# ESP32-C3 register map
Vendor: ESPRESSIF SYSTEMS (SHANGHAI) CO., LTD.; Series: ESP32 C-Series; File version: 19
CPU: RV32IMC r0p0, little endian, no MPU, no FPU, 0 interrupt priority bits
Address unit: 32 bits
Registers are 32-bit, read-write, reset 0x0 unless marked. A register's access mark holds for its fields unless they carry their own. Offsets are from the block's base; [hi:lo] are bit positions; {n}, {i} and the like mark numbered series.

## RTC_CNTL — Real-Time Clock Control
Base 0x60008000
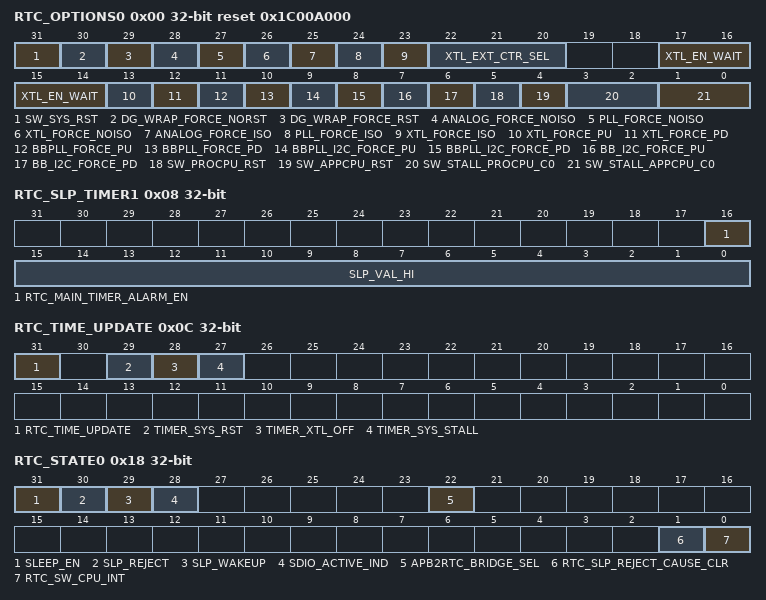
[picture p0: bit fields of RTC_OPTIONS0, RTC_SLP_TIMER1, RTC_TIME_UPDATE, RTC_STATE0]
0x00 RTC_OPTIONS0 access per field reset 0x1C00A000 — rtc configure register
  [31] SW_SYS_RST wo — SW system reset
  [30] DG_WRAP_FORCE_NORST rw — digital core force no reset in deep sleep
  [29] DG_WRAP_FORCE_RST rw — digital wrap force reset in deep sleep
  [28] ANALOG_FORCE_NOISO rw — analog configure
  [27] PLL_FORCE_NOISO rw — analog configure
  [26] XTL_FORCE_NOISO rw — analog configure
  [25] ANALOG_FORCE_ISO rw — analog configure
  [24] PLL_FORCE_ISO rw — analog configure
  [23] XTL_FORCE_ISO rw — analog configure
  [22:20] XTL_EXT_CTR_SEL rw — analog configure
  [17:14] XTL_EN_WAIT rw — wait bias_sleep and current source wakeup
  [13] XTL_FORCE_PU rw — crystall force power up
  [12] XTL_FORCE_PD rw — crystall force power down
  [11] BBPLL_FORCE_PU rw — BB_PLL force power up
  [10] BBPLL_FORCE_PD rw — BB_PLL force power down
  [9] BBPLL_I2C_FORCE_PU rw — BB_PLL_I2C force power up
  [8] BBPLL_I2C_FORCE_PD rw — BB_PLL _I2C force power down
  [7] BB_I2C_FORCE_PU rw — BB_I2C force power up
  [6] BB_I2C_FORCE_PD rw — BB_I2C force power down
  [5] SW_PROCPU_RST wo — PRO CPU SW reset
  [4] SW_APPCPU_RST wo — APP CPU SW reset
  [3:2] SW_STALL_PROCPU_C0 rw — {reg_sw_stall_procpu_c1[5:0], reg_sw_stall_procpu_c0[1:0]} == 0x86 will stall PRO CPU
  [1:0] SW_STALL_APPCPU_C0 rw — {reg_sw_stall_appcpu_c1[5:0], reg_sw_stall_appcpu_c0[1:0]} == 0x86 will stall APP CPU
0x04 RTC_SLP_TIMER0 — rtc configure register
  [31:0] SLP_VAL_LO — configure the sleep time
0x08 RTC_SLP_TIMER1 access per field — rtc configure register
  [16] RTC_MAIN_TIMER_ALARM_EN wo — timer alarm enable bit
  [15:0] SLP_VAL_HI rw — RTC sleep timer high 16 bits
0x0C RTC_TIME_UPDATE access per field — rtc configure register
  [31] RTC_TIME_UPDATE wo — Set 1: to update register with RTC timer
  [29] TIMER_SYS_RST rw — enable to record system reset time
  [28] TIMER_XTL_OFF rw — Enable to record 40M XTAL OFF time
  [27] TIMER_SYS_STALL rw — Enable to record system stall time
0x10 RTC_TIME_LOW0 ro — rtc configure register
  [31:0] RTC_TIMER_VALUE0_LOW — RTC timer low 32 bits
0x14 RTC_TIME_HIGH0 ro — rtc configure register
  [15:0] RTC_TIMER_VALUE0_HIGH — RTC timer high 16 bits
0x18 RTC_STATE0 access per field — rtc configure register
  [31] SLEEP_EN rw — sleep enable bit
  [30] SLP_REJECT rw — leep reject bit
  [29] SLP_WAKEUP rw — leep wakeup bit
  [28] SDIO_ACTIVE_IND ro — SDIO active indication
  [22] APB2RTC_BRIDGE_SEL rw — 1: APB to RTC using bridge
  [1] RTC_SLP_REJECT_CAUSE_CLR wo — clear rtc sleep reject cause
  [0] RTC_SW_CPU_INT wo — rtc software interrupt to main cpu
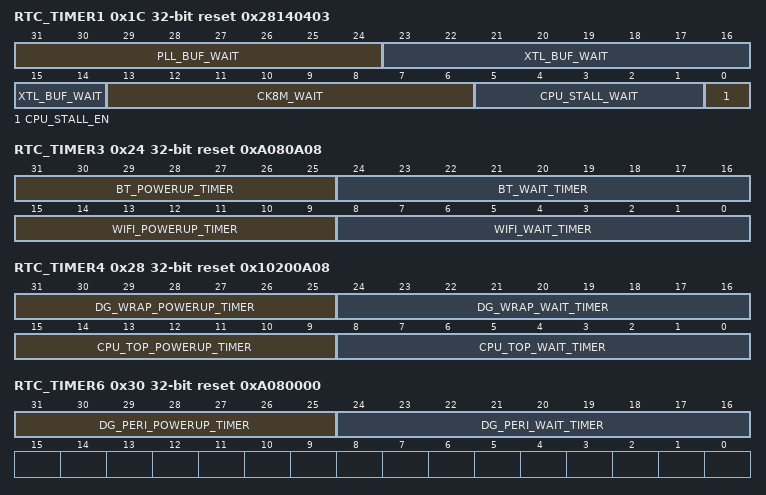
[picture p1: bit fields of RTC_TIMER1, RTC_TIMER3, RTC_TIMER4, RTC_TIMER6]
0x1C RTC_TIMER1 reset 0x28140403 — rtc configure register
  [31:24] PLL_BUF_WAIT — PLL wait cycles in slow_clk_rtc
  [23:14] XTL_BUF_WAIT — XTAL wait cycles in slow_clk_rtc
  [13:6] CK8M_WAIT — CK8M wait cycles in slow_clk_rtc
  [5:1] CPU_STALL_WAIT — CPU stall wait cycles in fast_clk_rtc
  [0] CPU_STALL_EN — CPU stall enable bit
0x20 RTC_TIMER2 reset 0x1000000 — rtc configure register
  [31:24] MIN_TIME_CK8M_OFF — minimal cycles in slow_clk_rtc for CK8M in power down state
0x24 RTC_TIMER3 reset 0xA080A08 — rtc configure register
  [31:25] BT_POWERUP_TIMER — bt power domain power on time
  [24:16] BT_WAIT_TIMER — bt power domain wakeup time
  [15:9] WIFI_POWERUP_TIMER — wifi power domain power on time
  [8:0] WIFI_WAIT_TIMER — wifi power domain wakeup time
0x28 RTC_TIMER4 reset 0x10200A08 — rtc configure register
  [31:25] DG_WRAP_POWERUP_TIMER — digital wrap power domain power on time
  [24:16] DG_WRAP_WAIT_TIMER — digital wrap power domain wakeup time
  [15:9] CPU_TOP_POWERUP_TIMER — cpu top power domain power on time
  [8:0] CPU_TOP_WAIT_TIMER — cpu top power domain wakeup time
0x2C RTC_TIMER5 reset 0x8000 — rtc configure register
  [15:8] MIN_SLP_VAL — minimal sleep cycles in slow_clk_rtc
0x30 RTC_TIMER6 reset 0xA080000 — rtc configure register
  [31:25] DG_PERI_POWERUP_TIMER — digital peri power domain power on time
  [24:16] DG_PERI_WAIT_TIMER — digital peri power domain wakeup time
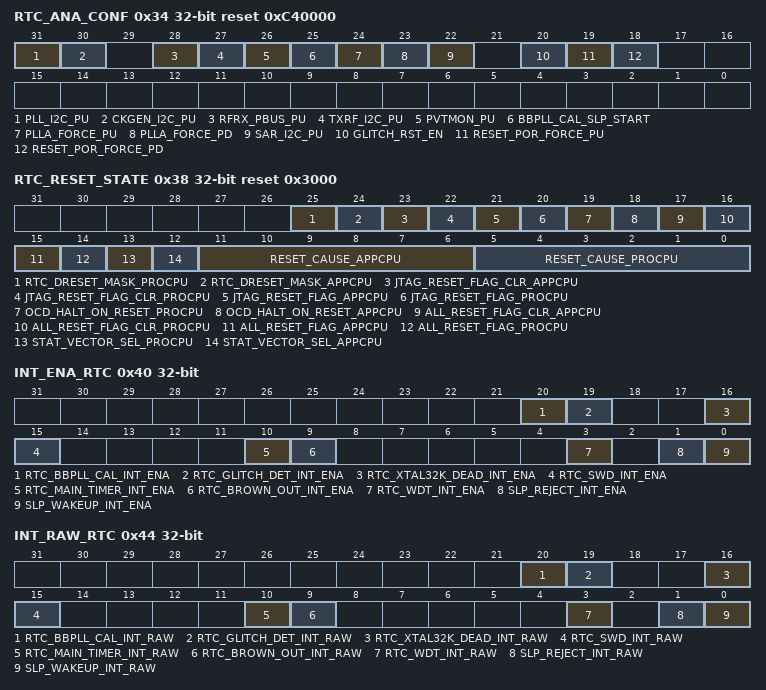
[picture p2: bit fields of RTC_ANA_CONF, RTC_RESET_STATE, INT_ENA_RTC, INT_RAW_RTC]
0x34 RTC_ANA_CONF reset 0xC40000 — rtc configure register
  [31] PLL_I2C_PU — power up pll i2c
  [30] CKGEN_I2C_PU — 1: CKGEN_I2C power up
  [28] RFRX_PBUS_PU — 1: RFRX_PBUS power up
  [27] TXRF_I2C_PU — 1: TXRF_I2C power up
  [26] PVTMON_PU — 1: PVTMON power up
  [25] BBPLL_CAL_SLP_START — start BBPLL calibration during sleep
  [24] PLLA_FORCE_PU — PLLA force power up
  [23] PLLA_FORCE_PD — PLLA force power down
  [22] SAR_I2C_PU — PLLA force power up
  [20] GLITCH_RST_EN — enable glitch reset
  [19] RESET_POR_FORCE_PU — force bypass i2c power on reset
  [18] RESET_POR_FORCE_PD — force no bypass i2c power on reset
0x38 RTC_RESET_STATE access per field reset 0x3000 — rtc configure register
  [25] RTC_DRESET_MASK_PROCPU rw — configure dreset configure
  [24] RTC_DRESET_MASK_APPCPU rw — configure dreset configure
  [23] JTAG_RESET_FLAG_CLR_APPCPU wo — configure jtag reset configure
  [22] JTAG_RESET_FLAG_CLR_PROCPU wo — configure jtag reset configure
  [21] JTAG_RESET_FLAG_APPCPU ro — configure jtag reset configure
  [20] JTAG_RESET_FLAG_PROCPU ro — configure jtag reset configure
  [19] OCD_HALT_ON_RESET_PROCPU rw — PROCPU OcdHaltOnReset
  [18] OCD_HALT_ON_RESET_APPCPU rw — APPCPU OcdHaltOnReset
  [17] ALL_RESET_FLAG_CLR_APPCPU wo — clear APP CPU reset flag
  [16] ALL_RESET_FLAG_CLR_PROCPU wo — clear PRO CPU reset_flag
  [15] ALL_RESET_FLAG_APPCPU ro — APP CPU reset flag
  [14] ALL_RESET_FLAG_PROCPU ro — PRO CPU reset_flag
  [13] STAT_VECTOR_SEL_PROCPU rw — PRO CPU state vector sel
  [12] STAT_VECTOR_SEL_APPCPU rw — APP CPU state vector sel
  [11:6] RESET_CAUSE_APPCPU ro — reset cause of APP CPU
  [5:0] RESET_CAUSE_PROCPU ro — reset cause of PRO CPU
0x3C RTC_WAKEUP_STATE reset 0x60000 — rtc configure register
  [31:15] RTC_WAKEUP_ENA — wakeup enable bitmap
0x40 INT_ENA_RTC — rtc configure register
  [20] RTC_BBPLL_CAL_INT_ENA — enbale bbpll cal end interrupt
  [19] RTC_GLITCH_DET_INT_ENA — enbale gitch det interrupt
  [16] RTC_XTAL32K_DEAD_INT_ENA — enable xtal32k_dead interrupt
  [15] RTC_SWD_INT_ENA — enable super watch dog interrupt
  [10] RTC_MAIN_TIMER_INT_ENA — enable RTC main timer interrupt
  [9] RTC_BROWN_OUT_INT_ENA — enable brown out interrupt
  [3] RTC_WDT_INT_ENA — enable RTC WDT interrupt
  [1] SLP_REJECT_INT_ENA — enable sleep reject interrupt
  [0] SLP_WAKEUP_INT_ENA — enable sleep wakeup interrupt
0x44 INT_RAW_RTC ro — rtc configure register
  [20] RTC_BBPLL_CAL_INT_RAW — bbpll cal end interrupt state
  [19] RTC_GLITCH_DET_INT_RAW — glitch_det_interrupt_raw
  [16] RTC_XTAL32K_DEAD_INT_RAW — xtal32k dead detection interrupt raw
  [15] RTC_SWD_INT_RAW — super watch dog interrupt raw
  [10] RTC_MAIN_TIMER_INT_RAW — RTC main timer interrupt raw
  [9] RTC_BROWN_OUT_INT_RAW — brown out interrupt raw
  [3] RTC_WDT_INT_RAW — RTC WDT interrupt raw
  [1] SLP_REJECT_INT_RAW — sleep reject interrupt raw
  [0] SLP_WAKEUP_INT_RAW — sleep wakeup interrupt raw
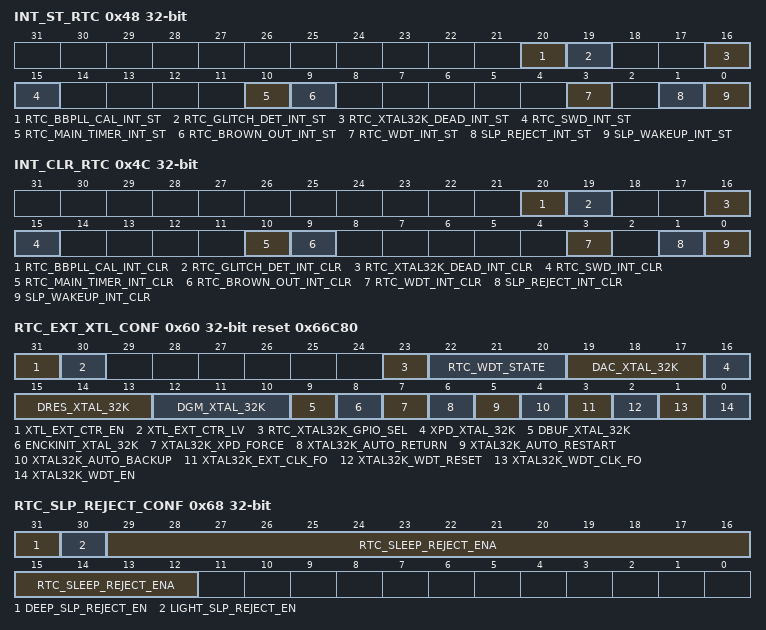
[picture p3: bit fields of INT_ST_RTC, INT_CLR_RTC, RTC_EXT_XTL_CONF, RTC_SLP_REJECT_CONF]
0x48 INT_ST_RTC ro — rtc configure register
  [20] RTC_BBPLL_CAL_INT_ST — bbpll cal end interrupt state
  [19] RTC_GLITCH_DET_INT_ST — glitch_det_interrupt state
  [16] RTC_XTAL32K_DEAD_INT_ST — xtal32k dead detection interrupt state
  [15] RTC_SWD_INT_ST — super watch dog interrupt state
  [10] RTC_MAIN_TIMER_INT_ST — RTC main timer interrupt state
  [9] RTC_BROWN_OUT_INT_ST — brown out interrupt state
  [3] RTC_WDT_INT_ST — RTC WDT interrupt state
  [1] SLP_REJECT_INT_ST — sleep reject interrupt state
  [0] SLP_WAKEUP_INT_ST — sleep wakeup interrupt state
0x4C INT_CLR_RTC wo — rtc configure register
  [20] RTC_BBPLL_CAL_INT_CLR — clear bbpll cal end interrupt state
  [19] RTC_GLITCH_DET_INT_CLR — Clear glitch det interrupt state
  [16] RTC_XTAL32K_DEAD_INT_CLR — Clear RTC WDT interrupt state
  [15] RTC_SWD_INT_CLR — Clear super watch dog interrupt state
  [10] RTC_MAIN_TIMER_INT_CLR — Clear RTC main timer interrupt state
  [9] RTC_BROWN_OUT_INT_CLR — Clear brown out interrupt state
  [3] RTC_WDT_INT_CLR — Clear RTC WDT interrupt state
  [1] SLP_REJECT_INT_CLR — Clear sleep reject interrupt state
  [0] SLP_WAKEUP_INT_CLR — Clear sleep wakeup interrupt state
{0x50+4i} RTC_STORE{i} (i=0..3) — rtc configure register
  [31:0] RTC_SCRATCH{i} — reserved register
0x60 RTC_EXT_XTL_CONF access per field reset 0x66C80 — rtc configure register
  [31] XTL_EXT_CTR_EN rw — enable gpio configure xtal power on
  [30] XTL_EXT_CTR_LV rw — 0: power down XTAL at high level
  [23] RTC_XTAL32K_GPIO_SEL rw — XTAL_32K sel. 0: external XTAL_32K
  [22:20] RTC_WDT_STATE ro — state of 32k_wdt
  [19:17] DAC_XTAL_32K rw
  [16] XPD_XTAL_32K rw
  [15:13] DRES_XTAL_32K rw
  [12:10] DGM_XTAL_32K rw — xtal_32k gm control
  [9] DBUF_XTAL_32K rw — 0: single-end buffer 1: differential buffer
  [8] ENCKINIT_XTAL_32K rw — apply an internal clock to help xtal 32k to start
  [7] XTAL32K_XPD_FORCE rw — Xtal 32k xpd control by sw or fsm
  [6] XTAL32K_AUTO_RETURN rw — xtal 32k switch back xtal when xtal is restarted
  [5] XTAL32K_AUTO_RESTART rw — xtal 32k restart xtal when xtal is dead
  [4] XTAL32K_AUTO_BACKUP rw — xtal 32k switch to back up clock when xtal is dead
  [3] XTAL32K_EXT_CLK_FO rw — xtal 32k external xtal clock force on
  [2] XTAL32K_WDT_RESET rw — xtal 32k watch dog sw reset
  [1] XTAL32K_WDT_CLK_FO rw — xtal 32k watch dog clock force on
  [0] XTAL32K_WDT_EN rw — xtal 32k watch dog enable
0x64 RTC_EXT_WAKEUP_CONF — rtc configure register
  [31] GPIO_WAKEUP_FILTER — enable filter for gpio wakeup event
0x68 RTC_SLP_REJECT_CONF — rtc configure register
  [31] DEEP_SLP_REJECT_EN — enable reject for deep sleep
  [30] LIGHT_SLP_REJECT_EN — enable reject for light sleep
  [29:12] RTC_SLEEP_REJECT_ENA — sleep reject enable
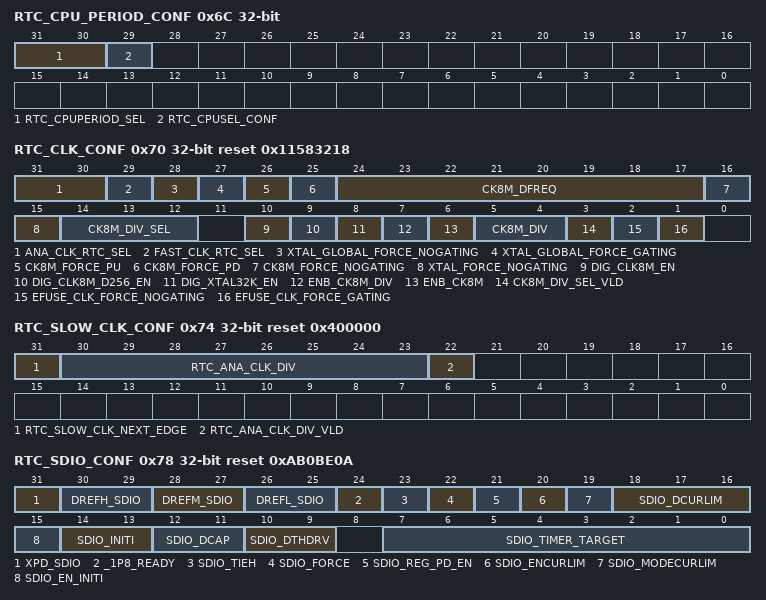
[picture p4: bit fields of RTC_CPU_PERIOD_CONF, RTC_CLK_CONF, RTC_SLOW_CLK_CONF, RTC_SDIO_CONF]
0x6C RTC_CPU_PERIOD_CONF — rtc configure register
  [31:30] RTC_CPUPERIOD_SEL — CPU clk sel option
  [29] RTC_CPUSEL_CONF — CPU sel option
0x70 RTC_CLK_CONF reset 0x11583218 — rtc configure register
  [31:30] ANA_CLK_RTC_SEL — slelect rtc slow clk
  [29] FAST_CLK_RTC_SEL — fast_clk_rtc sel. 0: XTAL div 4
  [28] XTAL_GLOBAL_FORCE_NOGATING — force bypass xtal clk gating
  [27] XTAL_GLOBAL_FORCE_GATING — force enable xtal clk gating
  [26] CK8M_FORCE_PU — CK8M force power up
  [25] CK8M_FORCE_PD — CK8M force power down
  [24:17] CK8M_DFREQ
  [16] CK8M_FORCE_NOGATING — CK8M force no gating during sleep
  [15] XTAL_FORCE_NOGATING — XTAL force no gating during sleep
  [14:12] CK8M_DIV_SEL — divider = reg_ck8m_div_sel + 1
  [10] DIG_CLK8M_EN — enable CK8M for digital core (no relationship with RTC core)
  [9] DIG_CLK8M_D256_EN — enable CK8M_D256_OUT for digital core (no relationship with RTC core)
  [8] DIG_XTAL32K_EN — enable CK_XTAL_32K for digital core (no relationship with RTC core)
  [7] ENB_CK8M_DIV — 1: CK8M_D256_OUT is actually CK8M
  [6] ENB_CK8M — disable CK8M and CK8M_D256_OUT
  [5:4] CK8M_DIV — CK8M_D256_OUT divider. 00: div128
  [3] CK8M_DIV_SEL_VLD — used to sync reg_ck8m_div_sel bus. Clear vld before set reg_ck8m_div_sel
  [2] EFUSE_CLK_FORCE_NOGATING
  [1] EFUSE_CLK_FORCE_GATING
0x74 RTC_SLOW_CLK_CONF reset 0x400000 — rtc configure register
  [31] RTC_SLOW_CLK_NEXT_EDGE — flag rtc_slow_clk_next_edge
  [30:23] RTC_ANA_CLK_DIV — the clk divider num of RTC_CLK
  [22] RTC_ANA_CLK_DIV_VLD — used to sync div bus. clear vld before set reg_rtc_ana_clk_div
0x78 RTC_SDIO_CONF access per field reset 0xAB0BE0A — rtc configure register
  [31] XPD_SDIO rw
  [30:29] DREFH_SDIO rw — SW option for DREFH_SDIO. Only active when reg_sdio_force = 1
  [28:27] DREFM_SDIO rw — SW option for DREFM_SDIO. Only active when reg_sdio_force = 1
  [26:25] DREFL_SDIO rw — SW option for DREFL_SDIO. Only active when reg_sdio_force = 1
  [24] _1P8_READY ro — read only register for REG1P8_READY
  [23] SDIO_TIEH rw — SW option for SDIO_TIEH. Only active when reg_sdio_force = 1
  [22] SDIO_FORCE rw — 1: use SW option to control SDIO_REG
  [21] SDIO_REG_PD_EN rw — power down SDIO_REG in sleep. Only active when reg_sdio_force = 0
  [20] SDIO_ENCURLIM rw — enable current limit
  [19] SDIO_MODECURLIM rw — select current limit mode
  [18:16] SDIO_DCURLIM rw — tune current limit threshold when tieh = 0. About 800mA/(8+d)
  [15] SDIO_EN_INITI rw — 0 to set init[1:0]=0
  [14:13] SDIO_INITI rw — add resistor from ldo output to ground. 0: no res
  [12:11] SDIO_DCAP rw — ability to prevent LDO from overshoot
  [10:9] SDIO_DTHDRV rw — Tieh = 1 mode drive ability. Initially set to 0 to limit charge current
  [7:0] SDIO_TIMER_TARGET rw — timer count to apply reg_sdio_dcap after sdio power on
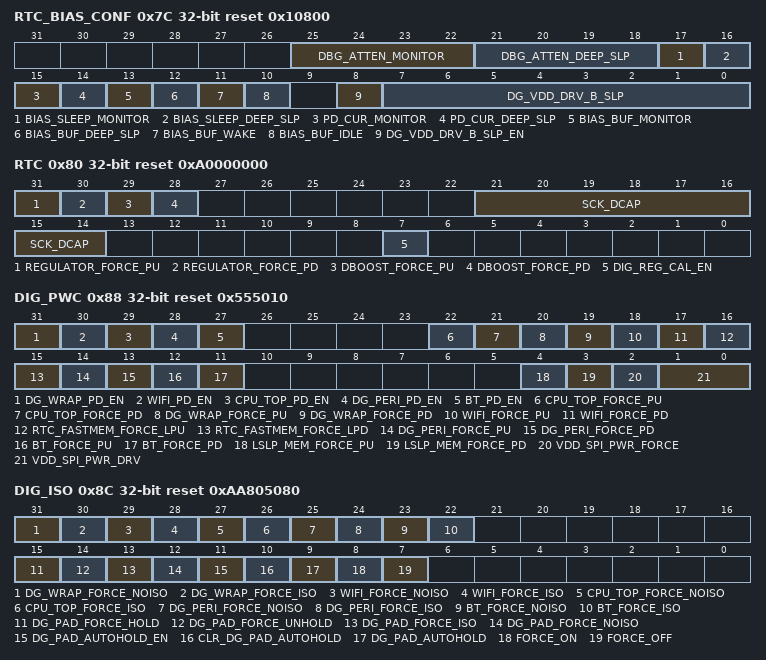
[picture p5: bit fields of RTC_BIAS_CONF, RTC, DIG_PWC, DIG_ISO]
0x7C RTC_BIAS_CONF reset 0x10800 — rtc configure register
  [25:22] DBG_ATTEN_MONITOR — DBG_ATTEN when rtc in monitor state
  [21:18] DBG_ATTEN_DEEP_SLP — DBG_ATTEN when rtc in sleep state
  [17] BIAS_SLEEP_MONITOR — bias_sleep when rtc in monitor state
  [16] BIAS_SLEEP_DEEP_SLP — bias_sleep when rtc in sleep_state
  [15] PD_CUR_MONITOR — xpd cur when rtc in monitor state
  [14] PD_CUR_DEEP_SLP — xpd cur when rtc in sleep_state
  [13] BIAS_BUF_MONITOR — bias buf when rtc in monitor state
  [12] BIAS_BUF_DEEP_SLP — bias buf when rtc in sleep state
  [11] BIAS_BUF_WAKE — bias buf when rtc in wakeup state
  [10] BIAS_BUF_IDLE — bias buf when rtc in normal work state
  [8] DG_VDD_DRV_B_SLP_EN
  [7:0] DG_VDD_DRV_B_SLP
0x80 RTC reset 0xA0000000 — rtc configure register
  [31] REGULATOR_FORCE_PU — RTC_REG force power up
  [30] REGULATOR_FORCE_PD — RTC_REG force power down (for RTC_REG power down means decrease the voltage to 0.8v or lower )
  [29] DBOOST_FORCE_PU — RTC_DBOOST force power up
  [28] DBOOST_FORCE_PD — RTC_DBOOST force power down
  [21:14] SCK_DCAP
  [7] DIG_REG_CAL_EN — software enable digital regulator cali
0x84 RTC_PWC — rtc configure register
  [21] RTC_PAD_FORCE_HOLD
0x88 DIG_PWC reset 0x555010 — rtc configure register
  [31] DG_WRAP_PD_EN — enable power down digital wrap in sleep
  [30] WIFI_PD_EN — enable power down wifi in sleep
  [29] CPU_TOP_PD_EN — enable power down cpu in sleep
  [28] DG_PERI_PD_EN — enable power down digital peri in sleep
  [27] BT_PD_EN — enable power down bt in sleep
  [22] CPU_TOP_FORCE_PU — cpu force power up
  [21] CPU_TOP_FORCE_PD — cpu core force power down
  [20] DG_WRAP_FORCE_PU — digital core force power up
  [19] DG_WRAP_FORCE_PD — digital core force power down
  [18] WIFI_FORCE_PU — wifi force power up
  [17] WIFI_FORCE_PD — wifi force power down
  [16] RTC_FASTMEM_FORCE_LPU — fastmemory donlt entry retention mode in sleep
  [15] RTC_FASTMEM_FORCE_LPD — fastmemory retention mode in sleep
  [14] DG_PERI_FORCE_PU — digital peri force power up
  [13] DG_PERI_FORCE_PD — digital peri force power down
  [12] BT_FORCE_PU — bt force power up
  [11] BT_FORCE_PD — bt force power down
  [4] LSLP_MEM_FORCE_PU — memories in digital core force PU in sleep
  [3] LSLP_MEM_FORCE_PD — memories in digital core force PD in sleep
  [2] VDD_SPI_PWR_FORCE — vdd_spi drv use software value
  [1:0] VDD_SPI_PWR_DRV — vdd_spi drv's software value
0x8C DIG_ISO access per field reset 0xAA805080 — rtc configure register
  [31] DG_WRAP_FORCE_NOISO rw — digital core force no ISO
  [30] DG_WRAP_FORCE_ISO rw — digital core force ISO
  [29] WIFI_FORCE_NOISO rw
  [28] WIFI_FORCE_ISO rw
  [27] CPU_TOP_FORCE_NOISO rw — cpu force no ISO
  [26] CPU_TOP_FORCE_ISO rw — cpu force ISO
  [25] DG_PERI_FORCE_NOISO rw — digital peri force no ISO
  [24] DG_PERI_FORCE_ISO rw — Digital peri force ISO
  [23] BT_FORCE_NOISO rw
  [22] BT_FORCE_ISO rw
  [15] DG_PAD_FORCE_HOLD rw — digital pad force hold
  [14] DG_PAD_FORCE_UNHOLD rw — digital pad force un-hold
  [13] DG_PAD_FORCE_ISO rw — digital pad force ISO
  [12] DG_PAD_FORCE_NOISO rw — digital pad force no ISO
  [11] DG_PAD_AUTOHOLD_EN rw — digital pad enable auto-hold
  [10] CLR_DG_PAD_AUTOHOLD wo — wtite only register to clear digital pad auto-hold
  [9] DG_PAD_AUTOHOLD ro — read only register to indicate digital pad auto-hold status
  [8] FORCE_ON rw — DIG_ISO force on
  [7] FORCE_OFF rw — DIG_ISO force off
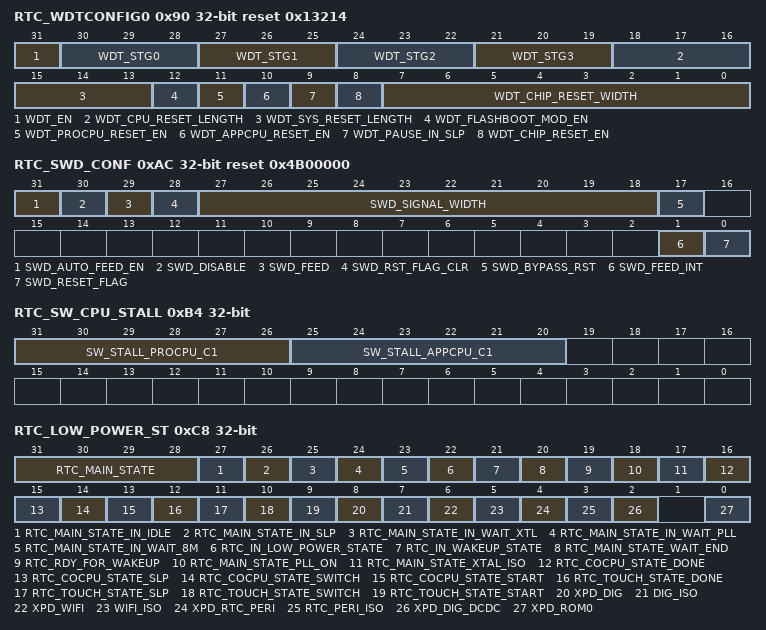
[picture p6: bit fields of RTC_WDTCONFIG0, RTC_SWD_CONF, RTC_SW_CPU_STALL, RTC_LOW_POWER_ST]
0x90 RTC_WDTCONFIG0 reset 0x13214 — rtc configure register
  [31] WDT_EN — enable rtc wdt
  [30-3n:28-3n] WDT_STG{n} (n=0..3) — 1: interrupt stage en
  [18:16] WDT_CPU_RESET_LENGTH — CPU reset counter length
  [15:13] WDT_SYS_RESET_LENGTH — system reset counter length
  [12] WDT_FLASHBOOT_MOD_EN — enable WDT in flash boot
  [11] WDT_PROCPU_RESET_EN — enable WDT reset PRO CPU
  [10] WDT_APPCPU_RESET_EN — enable WDT reset APP CPU
  [9] WDT_PAUSE_IN_SLP — pause WDT in sleep
  [8] WDT_CHIP_RESET_EN — wdt reset whole chip enable
  [7:0] WDT_CHIP_RESET_WIDTH — chip reset siginal pulse width
0x94 RTC_WDTCONFIG1 reset 0x30D40 — rtc configure register
  [31:0] WDT_STG0_HOLD — the hold time of stage0
0x98 RTC_WDTCONFIG2 reset 0x13880 — rtc configure register
  [31:0] WDT_STG1_HOLD — the hold time of stage1
0x9C RTC_WDTCONFIG3 reset 0xFFF — rtc configure register
  [31:0] WDT_STG2_HOLD — the hold time of stage2
0xA0 RTC_WDTCONFIG4 reset 0xFFF — rtc configure register
  [31:0] WDT_STG3_HOLD — the hold time of stage3
0xA4 RTC_WDTFEED wo — rtc configure register
  [31] RTC_WDT_FEED — sw feed rtc wdt
0xA8 RTC_WDTWPROTECT — rtc configure register
  [31:0] WDT_WKEY — the key of rtc wdt
0xAC RTC_SWD_CONF access per field reset 0x4B00000 — rtc configure register
  [31] SWD_AUTO_FEED_EN rw — automatically feed swd when int comes
  [30] SWD_DISABLE rw — disabel SWD
  [29] SWD_FEED wo — Sw feed swd
  [28] SWD_RST_FLAG_CLR wo — reset swd reset flag
  [27:18] SWD_SIGNAL_WIDTH rw — adjust signal width send to swd
  [17] SWD_BYPASS_RST rw — Bypass swd rst
  [1] SWD_FEED_INT ro — swd interrupt for feeding
  [0] SWD_RESET_FLAG ro
0xB0 RTC_SWD_WPROTECT — rtc configure register
  [31:0] SWD_WKEY — the key of super wdt
0xB4 RTC_SW_CPU_STALL — rtc configure register
  [31:26] SW_STALL_PROCPU_C1 — stall cpu by software
  [25:20] SW_STALL_APPCPU_C1 — {reg_sw_stall_appcpu_c1[5:0]
{0xA8+4i} RTC_STORE{i} (i=4..7) — rtc configure register
  [31:0] RTC_SCRATCH{i} — reserved register
0xC8 RTC_LOW_POWER_ST ro — rtc configure register
  [31:28] RTC_MAIN_STATE — rtc main state machine status
  [27] RTC_MAIN_STATE_IN_IDLE — rtc main state machine is in idle state
  [26] RTC_MAIN_STATE_IN_SLP — rtc main state machine is in sleep state
  [25] RTC_MAIN_STATE_IN_WAIT_XTL — rtc main state machine is in wait xtal state
  [24] RTC_MAIN_STATE_IN_WAIT_PLL — rtc main state machine is in wait pll state
  [23] RTC_MAIN_STATE_IN_WAIT_8M — rtc main state machine is in wait 8m state
  [22] RTC_IN_LOW_POWER_STATE — rtc main state machine is in the states of low power
  [21] RTC_IN_WAKEUP_STATE — rtc main state machine is in the states of wakeup process
  [20] RTC_MAIN_STATE_WAIT_END — rtc main state machine has been waited for some cycles
  [19] RTC_RDY_FOR_WAKEUP — rtc is ready to receive wake up trigger from wake up source
  [18] RTC_MAIN_STATE_PLL_ON — rtc main state machine is in states that pll should be running
  [17] RTC_MAIN_STATE_XTAL_ISO — no use any more
  [16] RTC_COCPU_STATE_DONE — ulp/cocpu is done
  [15] RTC_COCPU_STATE_SLP — ulp/cocpu is in sleep state
  [14] RTC_COCPU_STATE_SWITCH — ulp/cocpu is about to working. Switch rtc main state
  [13] RTC_COCPU_STATE_START — ulp/cocpu should start to work
  [12] RTC_TOUCH_STATE_DONE — touch is done
  [11] RTC_TOUCH_STATE_SLP — touch is in sleep state
  [10] RTC_TOUCH_STATE_SWITCH — touch is about to working. Switch rtc main state
  [9] RTC_TOUCH_STATE_START — touch should start to work
  [8] XPD_DIG — digital wrap power down
  [7] DIG_ISO — digital wrap iso
  [6] XPD_WIFI — wifi wrap power down
  [5] WIFI_ISO
  [4] XPD_RTC_PERI — rtc peripheral power down
  [3] RTC_PERI_ISO — rtc peripheral iso
  [2] XPD_DIG_DCDC — External DCDC power down
  [0] XPD_ROM0 — rom0 power down
0xCC RTC_DIAG0 ro — rtc configure register
  [31:0] RTC_LOW_POWER_DIAG1
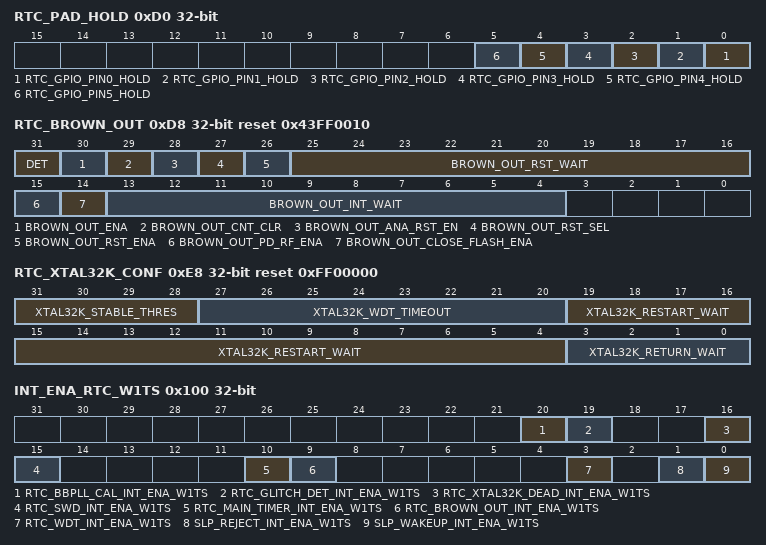
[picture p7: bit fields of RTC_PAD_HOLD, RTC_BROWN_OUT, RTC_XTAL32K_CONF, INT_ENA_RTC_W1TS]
0xD0 RTC_PAD_HOLD — rtc configure register
  [n] RTC_GPIO_PIN{n}_HOLD (n=0..5) — the hold configure of rtc gpio{n}
0xD4 DIG_PAD_HOLD — rtc configure register
  [31:0] DIG_PAD_HOLD — the configure of digital pad
0xD8 RTC_BROWN_OUT access per field reset 0x43FF0010 — rtc configure register
  [31] DET ro — the flag of brown det from analog
  [30] BROWN_OUT_ENA rw — enable brown out
  [29] BROWN_OUT_CNT_CLR wo — clear brown out counter
  [28] BROWN_OUT_ANA_RST_EN rw — brown_out origin reset enable
  [27] BROWN_OUT_RST_SEL rw — 1: 4-pos reset
  [26] BROWN_OUT_RST_ENA rw — enable brown out reset
  [25:16] BROWN_OUT_RST_WAIT rw — brown out reset wait cycles
  [15] BROWN_OUT_PD_RF_ENA rw — enable power down RF when brown out happens
  [14] BROWN_OUT_CLOSE_FLASH_ENA rw — enable close flash when brown out happens
  [13:4] BROWN_OUT_INT_WAIT rw — brown out interrupt wait cycles
0xDC RTC_TIME_LOW1 ro — rtc configure register
  [31:0] RTC_TIMER_VALUE1_LOW — RTC timer low 32 bits
0xE0 RTC_TIME_HIGH1 ro — rtc configure register
  [15:0] RTC_TIMER_VALUE1_HIGH — RTC timer high 16 bits
0xE4 RTC_XTAL32K_CLK_FACTOR — rtc configure register
  [31:0] XTAL32K_CLK_FACTOR — xtal 32k watch dog backup clock factor
0xE8 RTC_XTAL32K_CONF reset 0xFF00000 — rtc configure register
  [31:28] XTAL32K_STABLE_THRES — if restarted xtal32k period is smaller than this
  [27:20] XTAL32K_WDT_TIMEOUT — If no clock detected for this amount of time
  [19:4] XTAL32K_RESTART_WAIT — cycles to wait to repower on xtal 32k
  [3:0] XTAL32K_RETURN_WAIT — cycles to wait to return noral xtal 32k
0xEC RTC_USB_CONF — rtc configure register
  [18] IO_MUX_RESET_DISABLE — disable io_mux reset
0xF0 RTC_SLP_REJECT_CAUSE ro — RTC_CNTL_RTC_SLP_REJECT_CAUSE_REG
  [17:0] REJECT_CAUSE — sleep reject cause
0xF4 RTC_OPTION1 — rtc configure register
  [0] FORCE_DOWNLOAD_BOOT — force chip entry download mode
0xF8 RTC_SLP_WAKEUP_CAUSE ro — RTC_CNTL_RTC_SLP_WAKEUP_CAUSE_REG
  [16:0] WAKEUP_CAUSE — sleep wakeup cause
0xFC RTC_ULP_CP_TIMER_1 reset 0xC800 — rtc configure register
  [31:8] ULP_CP_TIMER_SLP_CYCLE — sleep cycles for ULP-coprocessor timer
0x100 INT_ENA_RTC_W1TS wo — rtc configure register
  [20] RTC_BBPLL_CAL_INT_ENA_W1TS — enbale bbpll cal interrupt
  [19] RTC_GLITCH_DET_INT_ENA_W1TS — enbale gitch det interrupt
  [16] RTC_XTAL32K_DEAD_INT_ENA_W1TS — enable xtal32k_dead interrupt
  [15] RTC_SWD_INT_ENA_W1TS — enable super watch dog interrupt
  [10] RTC_MAIN_TIMER_INT_ENA_W1TS — enable RTC main timer interrupt
  [9] RTC_BROWN_OUT_INT_ENA_W1TS — enable brown out interrupt
  [3] RTC_WDT_INT_ENA_W1TS — enable RTC WDT interrupt
  [1] SLP_REJECT_INT_ENA_W1TS — enable sleep reject interrupt
  [0] SLP_WAKEUP_INT_ENA_W1TS — enable sleep wakeup interrupt
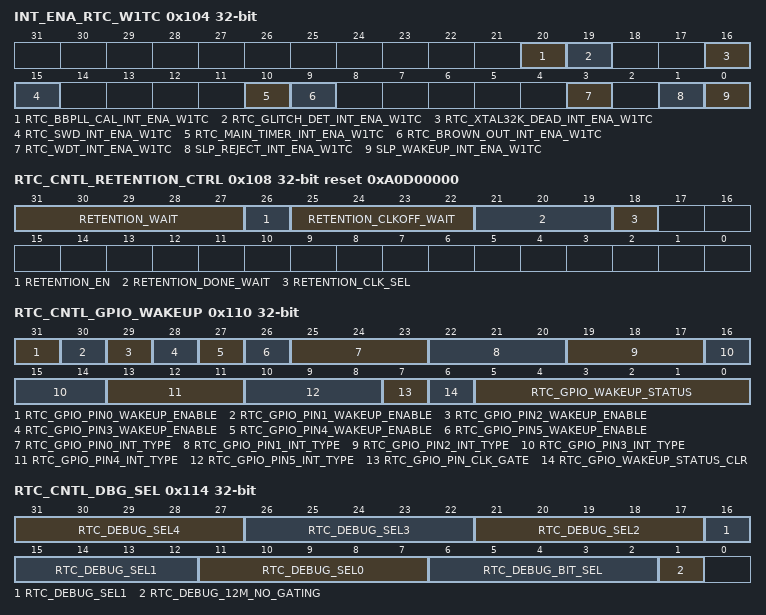
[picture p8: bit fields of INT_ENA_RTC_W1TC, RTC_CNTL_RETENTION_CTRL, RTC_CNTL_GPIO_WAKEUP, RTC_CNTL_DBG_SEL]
0x104 INT_ENA_RTC_W1TC wo — rtc configure register
  [20] RTC_BBPLL_CAL_INT_ENA_W1TC — clear bbpll cal interrupt enable
  [19] RTC_GLITCH_DET_INT_ENA_W1TC — clear gitch det interrupt enable
  [16] RTC_XTAL32K_DEAD_INT_ENA_W1TC — clear xtal32k_dead interrupt enable
  [15] RTC_SWD_INT_ENA_W1TC — clear super watch dog interrupt enable
  [10] RTC_MAIN_TIMER_INT_ENA_W1TC — Clear RTC main timer interrupt enable
  [9] RTC_BROWN_OUT_INT_ENA_W1TC — clear brown out interrupt enable
  [3] RTC_WDT_INT_ENA_W1TC — clear RTC WDT interrupt enable
  [1] SLP_REJECT_INT_ENA_W1TC — clear sleep reject interrupt enable
  [0] SLP_WAKEUP_INT_ENA_W1TC — clear sleep wakeup interrupt enable
0x108 RTC_CNTL_RETENTION_CTRL reset 0xA0D00000 — rtc configure register
  [31:27] RETENTION_WAIT — wait cycles for rention operation
  [26] RETENTION_EN — enable cpu retention when light sleep
  [25:22] RETENTION_CLKOFF_WAIT — Retention clkoff wait time
  [21:19] RETENTION_DONE_WAIT — Retention done wait time
  [18] RETENTION_CLK_SEL
0x10C RTC_FIB_SEL reset 0x7 — rtc configure register
  [2:0] RTC_FIB_SEL — select use analog fib signal
0x110 RTC_CNTL_GPIO_WAKEUP access per field — rtc configure register
  [31-n] RTC_GPIO_PIN{n}_WAKEUP_ENABLE rw (n=0..5) — enable wakeup from rtc gpio{n}
  [25-3n:23-3n] RTC_GPIO_PIN{n}_INT_TYPE rw (n=0..5) — configure gpio wakeup type
  [7] RTC_GPIO_PIN_CLK_GATE rw — enable rtc io clk gate
  [6] RTC_GPIO_WAKEUP_STATUS_CLR rw — clear rtc gpio wakeup flag
  [5:0] RTC_GPIO_WAKEUP_STATUS ro — rtc gpio wakeup flag
0x114 RTC_CNTL_DBG_SEL — rtc configure register
  [5n+11:5n+7] RTC_DEBUG_SEL{n} (n=0..4) — use for debug
  [6:2] RTC_DEBUG_BIT_SEL — use for debug
  [1] RTC_DEBUG_12M_NO_GATING — use for debug
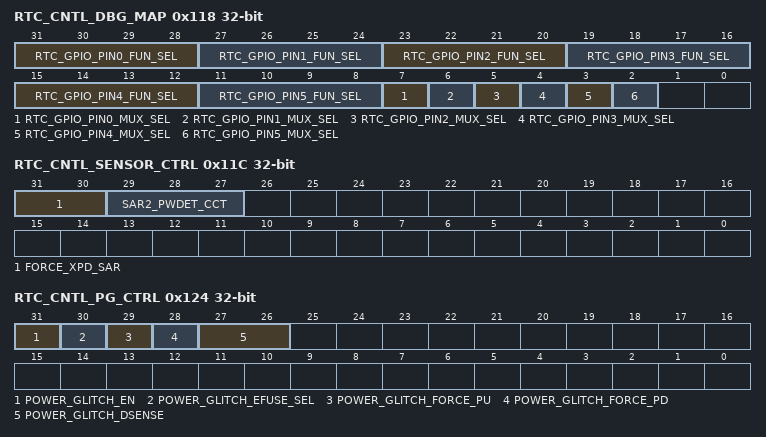
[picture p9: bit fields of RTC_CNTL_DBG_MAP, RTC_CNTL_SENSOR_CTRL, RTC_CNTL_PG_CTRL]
0x118 RTC_CNTL_DBG_MAP — rtc configure register
  [31-4n:28-4n] RTC_GPIO_PIN{n}_FUN_SEL (n=0..5) — use for debug
  [7-n] RTC_GPIO_PIN{n}_MUX_SEL (n=0..5) — use for debug
0x11C RTC_CNTL_SENSOR_CTRL — rtc configure register
  [31:30] FORCE_XPD_SAR — force power up SAR
  [29:27] SAR2_PWDET_CCT — reg_sar2_pwdet_cct
0x120 RTC_CNTL_DBG_SAR_SEL — rtc configure register
  [31:27] SAR_DEBUG_SEL — use for debug
0x124 RTC_CNTL_PG_CTRL — rtc configure register
  [31] POWER_GLITCH_EN — enable power glitch
  [30] POWER_GLITCH_EFUSE_SEL — use efuse value control power glitch enable
  [29] POWER_GLITCH_FORCE_PU — force enable power glitch
  [28] POWER_GLITCH_FORCE_PD — force disable power glitch
  [27:26] POWER_GLITCH_DSENSE — power glitch desense
0x1FC DATE reset 0x2007270 — rtc configure register
  [27:0] RTC_CNTL_DATE — verision
